# STM32L062 register map
File version: 1.1
CPU: CM0+ r0p0, little endian, MPU, no FPU, 4 interrupt priority bits
Registers are 32-bit, read-write, reset 0x0 unless marked. A register's access mark holds for its fields unless they carry their own. Offsets are from the block's base; [hi:lo] are bit positions.

## AES — Advanced encryption standard hardware accelerator
Base 0x40026000
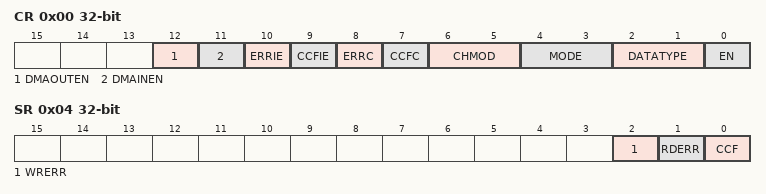
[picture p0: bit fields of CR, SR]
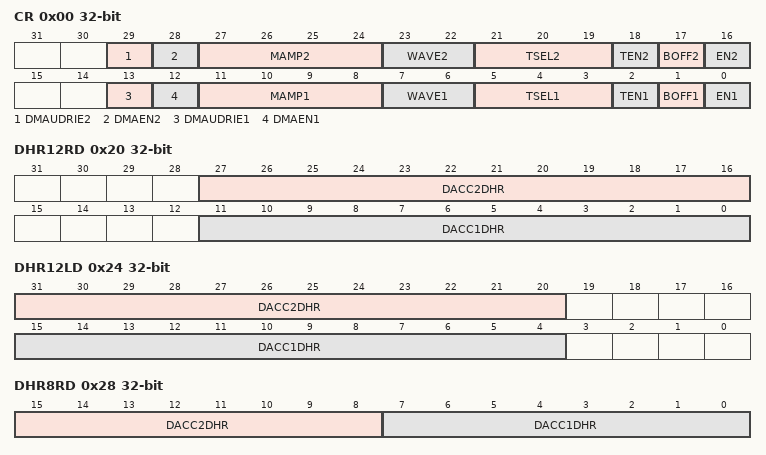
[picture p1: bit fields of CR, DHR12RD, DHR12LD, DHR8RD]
0x00 CR — control register
  [12] DMAOUTEN — Enable DMA management of data output phase
  [11] DMAINEN — Enable DMA management of data input phase
  [10] ERRIE — Error interrupt enable
  [9] CCFIE — CCF flag interrupt enable
  [8] ERRC — Error clear
  [7] CCFC — Computation Complete Flag Clear
  [6:5] CHMOD — AES chaining mode
  [4:3] MODE — AES operating mode
  [2:1] DATATYPE — Data type selection (for data in and data out to/from the cryptographic block)
  [0] EN — AES enable
0x04 SR ro — status register
  [2] WRERR — Write error flag
  [1] RDERR — Read error flag
  [0] CCF — Computation complete flag
0x08 DINR — data input register
  [31:0] AES_DINR — Data Input Register.
0x0C DOUTR ro — data output register
  [31:0] AES_DOUTR — Data output register
0x10 KEYR0 — key register 0
  [31:0] AES_KEYR0 — Data Output Register (LSB key [31:0])
0x14 KEYR1 — key register 1
  [31:0] AES_KEYR1 — AES key register (key [63:32])
0x18 KEYR2 — key register 2
  [31:0] AES_KEYR2 — AES key register (key [95:64])
0x1C KEYR3 — key register 3
  [31:0] AES_KEYR3 — AES key register (MSB key [127:96])
0x20 IVR0 — initialization vector register 0
  [31:0] AES_IVR0 — initialization vector register (LSB IVR [31:0])
0x24 IVR1 — initialization vector register 1
  [31:0] AES_IVR1 — Initialization Vector Register (IVR [63:32])
0x28 IVR2 — initialization vector register 2
  [31:0] AES_IVR2 — Initialization Vector Register (IVR [95:64])
0x2C IVR3 — initialization vector register 3
  [31:0] AES_IVR3 — Initialization Vector Register (MSB IVR [127:96])

## DAC — Digital-to-analog converter
Base 0x40007400
0x00 CR — control register
  [29] DMAUDRIE2 — DAC channel2 DMA underrun interrupt enable
  [28] DMAEN2 — DAC channel2 DMA enable
  [27:24] MAMP2 — DAC channel2 mask/amplitude selector
  [23:22] WAVE2 — DAC channel2 noise/triangle wave generation enable
  [21:19] TSEL2 — DAC channel2 trigger selection
  [18] TEN2 — DAC channel2 trigger enable
  [17] BOFF2 — DAC channel2 output buffer disable
  [16] EN2 — DAC channel2 enable
  [13] DMAUDRIE1 — DAC channel1 DMA Underrun Interrupt enable
  [12] DMAEN1 — DAC channel1 DMA enable
  [11:8] MAMP1 — DAC channel1 mask/amplitude selector
  [7:6] WAVE1 — DAC channel1 noise/triangle wave generation enable
  [5:3] TSEL1 — DAC channel1 trigger selection
  [2] TEN1 — DAC channel1 trigger enable
  [1] BOFF1 — DAC channel1 output buffer disable
  [0] EN1 — DAC channel1 enable
0x04 SWTRIGR wo — software trigger register
  [0] SWTRIG1 — DAC channel1 software trigger
0x08 DHR12R1 — channel1 12-bit right-aligned data holding register
  [11:0] DACC1DHR — DAC channel1 12-bit right-aligned data
0x0C DHR12L1 — channel1 12-bit left-aligned data holding register
  [15:4] DACC1DHR — DAC channel1 12-bit left-aligned data
0x10 DHR8R1 — channel1 8-bit right-aligned data holding register
  [7:0] DACC1DHR — DAC channel1 8-bit right-aligned data
0x14 DHR12R2 — channel2 12-bit right-aligned data holding register
  [11:0] DACC2DHR — DAC channel2 12-bit right-aligned data
0x18 DHR12L2 — channel2 12-bit left-aligned data holding register
  [15:4] DACC2DHR — DAC channel2 12-bit left-aligned data
0x1C DHR8R2 — channel2 8-bit right-aligned data holding register
  [7:0] DACC2DHR — DAC channel2 8-bit right-aligned data
0x20 DHR12RD — Dual DAC 12-bit right-aligned data holding register
  [27:16] DACC2DHR — DAC channel2 12-bit right-aligned data
  [11:0] DACC1DHR — DAC channel1 12-bit right-aligned data
0x24 DHR12LD — Dual DAC 12-bit left-aligned data holding register
  [31:20] DACC2DHR — DAC channel2 12-bit left-aligned data
  [15:4] DACC1DHR — DAC channel1 12-bit left-aligned data
0x28 DHR8RD — Dual DAC 8-bit right-aligned data holding register
  [15:8] DACC2DHR — DAC channel2 8-bit right-aligned data
  [7:0] DACC1DHR — DAC channel1 8-bit right-aligned data
0x2C DOR1 ro — channel1 data output register
  [11:0] DACC1DOR — DAC channel1 data output
0x30 DOR2 ro — channel2 data output register
  [11:0] DACC2DOR — DAC channel2 data output
0x34 SR — status register
  [13] DMAUDR1 — DAC channel1 DMA underrun flag

## Notices in the file
Copyright (c) 2023 STMicroelectronics.
SPDX-License-Identifier: Apache-2.0
Licensed under the Apache License, Version 2.0 (the "License");
you may not use this file except in compliance with the License.
You may obtain a copy of the License at
http://www.apache.org/licenses/LICENSE-2.0
Unless required by applicable law or agreed to in writing, software
distributed under the License is distributed on an "AS IS" BASIS,
WITHOUT WARRANTIES OR CONDITIONS OF ANY KIND, either express or implied.
See the License for the specific language governing permissions and
limitations under the License.
